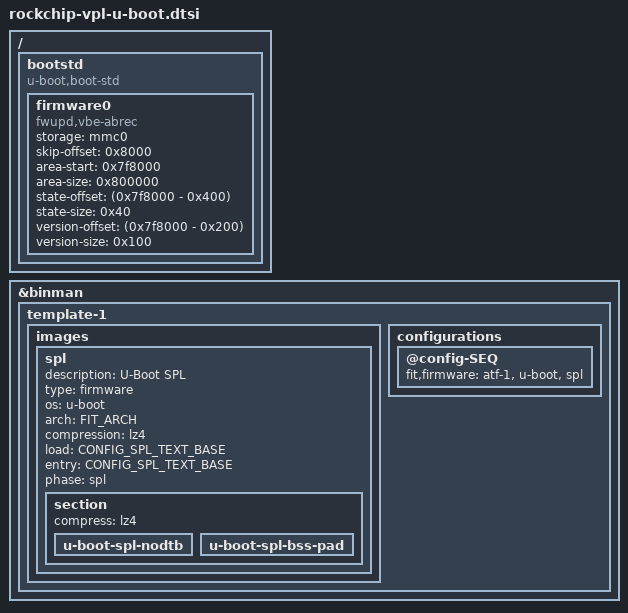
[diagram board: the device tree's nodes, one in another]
// SPDX-License-Identifier: GPL-2.0+
/*
 * Copyright (C) 2019 Jagan Teki <jagan@amarulasolutions.com>
 */

/ {
	bootstd {
		bootph-verify;
		compatible = "u-boot,boot-std";

		/*
		 * This is used for the VBE OS-request tests. A FAT filesystem
		 * created in a partition with the VBE information appearing
		 * before the partition starts.
		 *
		 * Offsets are aligned to the media block-size, typically 0x200
		 *
		 * The start of the VBE area is set at 8MB, adjusted for the
		 * skip-at-start offset. Before that is a block containing the
		 * version information and before that is the state. These could
		 * be stored in a different storage device if available, but so
		 * far VBE only supports MMC.
		 *
		 * The total area size is 8MB which should be enough for a FIT
		 * containing U-Boot and a number of devicetrees.
		 */
		firmware0 {
			bootph-verify;
			compatible = "fwupd,vbe-abrec";
			storage = "mmc0";
			skip-offset = <0x8000>;
			area-start = <0x7f8000>;
			area-size = <0x800000>;
			state-offset = <(0x7f8000 - 0x400)>;
			state-size = <0x40>;
			version-offset = <(0x7f8000 - 0x200)>;
			version-size = <0x100>;
		};
	};
};

&binman {
	template-1 {
		images {
			spl {
				description = "U-Boot SPL";
				type = "firmware";
				os = "u-boot";
				arch = FIT_ARCH;
				compression = "lz4";
				load = <CONFIG_SPL_TEXT_BASE>;
				entry = <CONFIG_SPL_TEXT_BASE>;
				phase = "spl";
				section {
					compress = "lz4";
					u-boot-spl-nodtb {
					};
					u-boot-spl-bss-pad {
					};
				};
			};
		};
		configurations {
			@config-SEQ {
				fit,firmware = "atf-1", "u-boot", "spl";
			};
		};
	};
};
